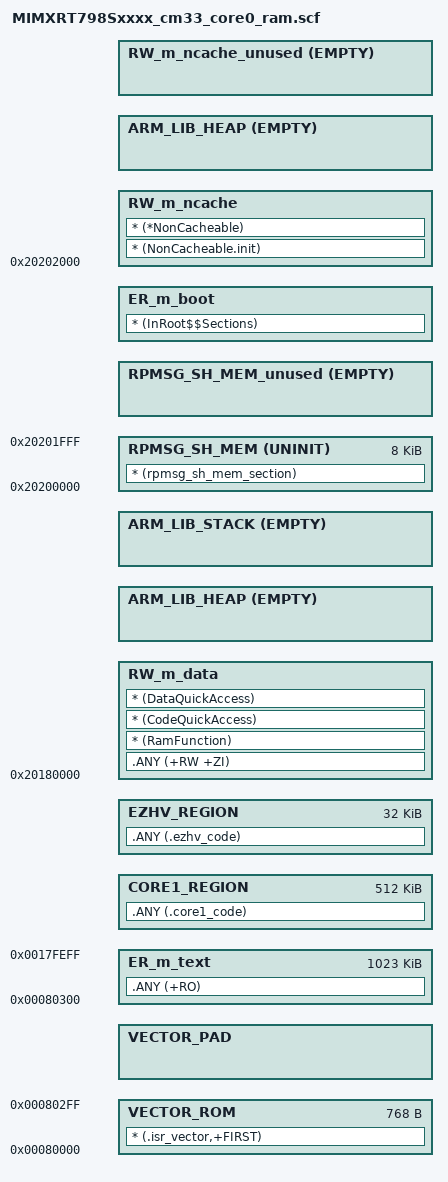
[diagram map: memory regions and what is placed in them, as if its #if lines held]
#!armclang --target=arm-arm-none-eabi -march=armv8-m.main -E -x c
/*
** ###################################################################
**     Processors:          MIMXRT798SGAWAR_cm33_core0
**                          MIMXRT798SGFOA_cm33_core0
**
**     Compiler:            Keil ARM C/C++ Compiler
**     Reference manual:    iMXRT700RM Rev.2 DraftA, 05/2024
**     Version:             rev. 2.0, 2024-05-28
**     Build:               b240528
**
**     Abstract:
**         Linker file for the Keil ARM C/C++ Compiler
**
**     Copyright 2016 Freescale Semiconductor, Inc.
**     Copyright 2016-2024 NXP
**     SPDX-License-Identifier: BSD-3-Clause
**
**     http:                 www.nxp.com
**     mail:                 support@nxp.com
**
** ###################################################################
*/


/* Sizes */
#if (defined(__stack_size__))
  #define Stack_Size                   __stack_size__
#else
  #define Stack_Size                   0x1000
#endif

#if (defined(__heap_size__))
  #define Heap_Size                    __heap_size__
#else
  #define Heap_Size                    0x1000
#endif

/* The SRAM region [0x000000-0x013FFF] is reserved for ROM bootloader execution. Can be reused after boot. */
/* The SRAM region [0x014000-0x07FFFF] is reserved for Non-cached shared memory or application data. */
/* The SRAM region [0x080000-0x77FFFF] is reserved for CPU0 application, last 5.5MB non-cacheable data for NPU/GPU/Display etc. */

#define m_flash_start                  0x28000000

#define m_boot_flash_conf_start        0x28000000
#define m_boot_flash_conf_size         0x00004000
#define m_boot_interrupts_start        0x28004000

#define m_interrupts_start             0x00080000
#define m_interrupts_size              0x00000300

#define m_data_start                   0x20180000
#define m_data_size                    0x00080000

#define m_text_start                   0x00080300
#define m_text_size                    0x000FFC00

#define m_core1_image_maximum_size     0x00080000
#define m_ezhv_image_maximum_size      0x00008000

#if (defined(__use_shmem__))
  #define m_rpmsg_sh_mem_start         0x20200000
  #define m_rpmsg_sh_mem_size          0x00002000
  #define m_ncache_start               0x20202000
  #define m_ncache_size                0x0057E000
#else
  #define m_ncache_start               0x20200000
  #define m_ncache_size                0x00580000
#endif
LR_m_flash_conf m_boot_flash_conf_start m_boot_interrupts_start-m_boot_flash_conf_start {
  FLASH_CONFIG + 0 { ; load address = execution address
    * (.flash_conf)
  }
}

LR_m_interrupts m_boot_interrupts_start m_interrupts_size+m_text_size {
  VECTOR_ROM m_interrupts_start m_interrupts_size {
    * (.isr_vector,+FIRST)
  }
  VECTOR_PAD +0 FILL 0x0 m_text_start-ImageLimit(VECTOR_ROM) {
  }
  ER_m_text m_text_start m_text_size {
    .ANY (+RO)
  }
  CORE1_REGION +0 ALIGN 16 m_core1_image_maximum_size {
    .ANY (.core1_code)
  }
  EZHV_REGION +0 ALIGN 16 m_ezhv_image_maximum_size {
    .ANY (.ezhv_code)
  }
#if (!defined(__heap_noncacheable__))
  RW_m_data m_data_start ALIGN 4 m_data_size-Stack_Size-Heap_Size { ; RW data
#else
  RW_m_data m_data_start ALIGN 4 m_data_size-Stack_Size { ; RW data
#endif
    .ANY (+RW +ZI)
    * (RamFunction)
    * (CodeQuickAccess)
    * (DataQuickAccess)
  }

#if (!defined(__heap_noncacheable__))
  ARM_LIB_HEAP +0 EMPTY Heap_Size {    ; Heap region growing up
  }
#endif
  ARM_LIB_STACK m_data_start+m_data_size EMPTY -Stack_Size { ; Stack region growing down
  }
#if (defined(__heap_noncacheable__))
  RW_m_ncache m_ncache_start m_ncache_size - Heap_Size { ; ncache data
#else
  RW_m_ncache m_ncache_start m_ncache_size { ; ncache data
#endif
    * (NonCacheable.init)
    * (*NonCacheable)
  }
#if (defined(__heap_noncacheable__))
  ARM_LIB_HEAP +0 EMPTY Heap_Size {    ; Heap region growing up
  }
  RW_m_ncache_unused +0 EMPTY m_ncache_size-ImageLength(RW_m_ncache)-Heap_Size { ; Empty region added for MPU configuration
  }
#else
  RW_m_ncache_unused +0 EMPTY m_ncache_size-ImageLength(RW_m_ncache) { ; Empty region added for MPU configuration
  }
#endif

#if (defined(__use_shmem__))
  RPMSG_SH_MEM m_rpmsg_sh_mem_start UNINIT m_rpmsg_sh_mem_size { ; Shared memory used by RPMSG
  * (rpmsg_sh_mem_section)
  }
  RPMSG_SH_MEM_unused +0 EMPTY m_rpmsg_sh_mem_size-ImageLength(RPMSG_SH_MEM) { ; Empty region added for MPU configuration
  }
#endif
}

LR_m_boot +0 {
  ER_m_boot +0 { ; load address = execution address
    * (InRoot$$Sections)
  }
}
